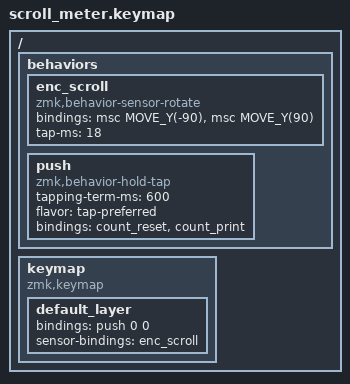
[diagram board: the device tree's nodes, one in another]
#include <behaviors.dtsi>
#include <dt-bindings/zmk/keys.h>
#include <dt-bindings/zmk/bt.h>
#include <dt-bindings/zmk/mouse.h>
#include <dt-bindings/zmk/pointing.h>

/ {
    behaviors {
        /* Encoder mouse-scroll: matches agent-keyboard's iphone-scroll-encoder
           branch tuning — speed 90 with tap-ms 18 emits ~1 wheel unit
           per detent on iOS, keeping macOS scroll-acceleration sane. */
        enc_scroll: enc_scroll {
            compatible = "zmk,behavior-sensor-rotate";
            #sensor-binding-cells = <0>;
            bindings = <&msc MOVE_Y(-90)>, <&msc MOVE_Y(90)>;
            tap-ms = <18>;
        };

        /* Encoder push:
             tap (≤600ms)   → type the running detent count as digits
             hold (>600ms)  → reset the counter to 0 */
        push: push {
            compatible = "zmk,behavior-hold-tap";
            #binding-cells = <2>;
            tapping-term-ms = <600>;
            flavor = "tap-preferred";
            bindings = <&count_reset>, <&count_print>;
        };
    };

    keymap {
        compatible = "zmk,keymap";

        default_layer {
            bindings = <&push 0 0>;
            sensor-bindings = <&enc_scroll>;
        };
    };
};
